# ATSAMC21N register map
Vendor: Microchip Technology Inc.; Series: SAMC21; File version: A
CPU: CM0+ r0p1, little endian, MPU, no FPU, VTOR, 2 interrupt priority bits, 31 interrupts
Registers are 32-bit, read-write, reset 0x0 unless marked. A register's access mark holds for its fields unless they carry their own. Offsets are from the block's base; [hi:lo] are bit positions; {n}, {i} and the like mark numbered series; 'fields as' and 'values as' point back to an identical list.

## AC — Analog Comparators
Base 0x42005000; register names take the prefix AC_
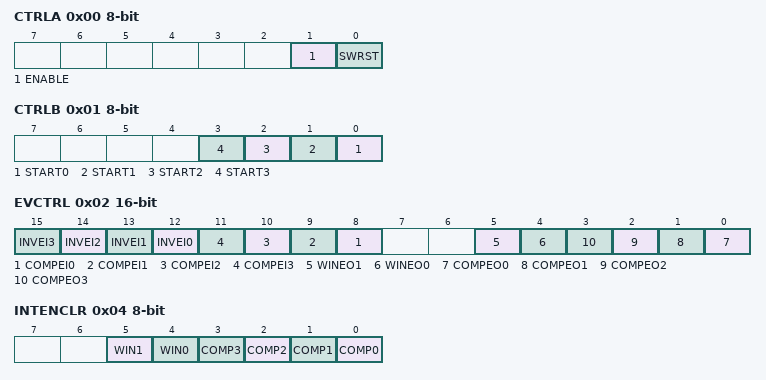
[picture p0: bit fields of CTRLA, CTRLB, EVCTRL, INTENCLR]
0x00 CTRLA 8-bit — Control A
  [1] ENABLE
  [0] SWRST wo — Software Reset
0x01 CTRLB 8-bit wo — Control B
  [n] START{n} (n=0..3) — Comparator {n} Start Comparison
0x02 EVCTRL 16-bit — Event Control
  [n+12] INVEI{n} (n=0..3) — Comparator {n} Input Event Invert Enable
  [n+8] COMPEI{n} (n=0..3) — Comparator {n} Event Input Enable
  [5] WINEO1 — Window 1 Event Output Enable
  [4] WINEO0 — Window 0 Event Output Enable
  [n] COMPEO{n} (n=0..3) — Comparator {n} Event Output Enable
0x04 INTENCLR 8-bit — Interrupt Enable Clear
  [5] WIN1 — Window 1 Interrupt Enable
  [4] WIN0 — Window 0 Interrupt Enable
  [n] COMP{n} (n=0..3) — Comparator {n} Interrupt Enable
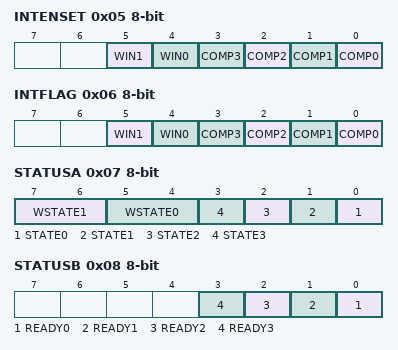
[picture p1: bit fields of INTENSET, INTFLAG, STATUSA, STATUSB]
0x05 INTENSET 8-bit — Interrupt Enable Set
  fields as INTENCLR
0x06 INTFLAG 8-bit — Interrupt Flag Status and Clear
  [5] WIN1 — Window 1
  [4] WIN0 — Window 0
  [n] COMP{n} (n=0..3) — Comparator {n}
0x07 STATUSA 8-bit ro
  [7:6] WSTATE1 — Window 1 Current State
    0=ABOVE (Signal is above window); 1=INSIDE (Signal is inside window); 2=BELOW (Signal is below window)
  [5:4] WSTATE0 — Window 0 Current State
    values as WSTATE1
  [n] STATE{n} (n=0..3) — Comparator {n} Current State
0x08 STATUSB 8-bit ro
  [n] READY{n} (n=0..3) — Comparator {n} Ready
0x09 DBGCTRL 8-bit — Debug Control
  [0] DBGRUN — Debug Run
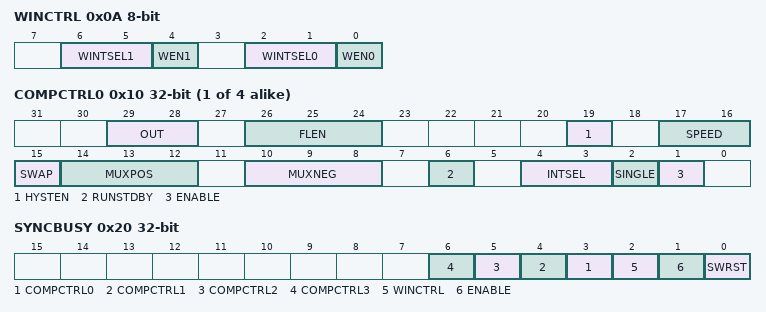
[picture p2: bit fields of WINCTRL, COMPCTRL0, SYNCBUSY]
0x0A WINCTRL 8-bit — Window Control
  [6:5] WINTSEL1 — Window 1 Interrupt Selection
    0=ABOVE (Interrupt on signal above window); 1=INSIDE (Interrupt on signal inside window); 2=BELOW (Interrupt on signal below window); 3=OUTSIDE (Interrupt on signal outside window)
  [4] WEN1 — Window 1 Mode Enable
  [2:1] WINTSEL0 — Window 0 Interrupt Selection
    values as WINTSEL1
  [0] WEN0 — Window 0 Mode Enable
{0xC+i} SCALER{i} (i=0..3) 8-bit — Scaler n
  [5:0] VALUE — Scaler Value
{0x10+4i} COMPCTRL{i} (i=0..3) — Comparator Control n
  [29:28] OUT — Output
    0=OFF (The output of COMPn is not routed to the COMPn I/O port); 1=ASYNC (The asynchronous output of COMPn is routed to the COMPn I/O port); 2=SYNC (The synchronous output (including filtering) of COMPn is routed to the COMPn I/O port)
  [26:24] FLEN — Filter Length
    0=OFF (No filtering); 1=MAJ3 (3-bit majority function (2 of 3)); 2=MAJ5 (5-bit majority function (3 of 5))
  [19] HYSTEN — Hysteresis Enable
  [17:16] SPEED — Speed Selection
    0=LOW (Low speed); 3=HIGH (High speed)
  [15] SWAP — Swap Inputs and Invert
  [14:12] MUXPOS — Positive Input Mux Selection
    {v}=PIN{v} (I/O pin {v}) (v=0..3); 4=VSCALE (VDD Scaler)
  [10:8] MUXNEG — Negative Input Mux Selection
    {v}=PIN{v} (I/O pin {v}) (v=0..3); 4=GND (Ground); 5=VSCALE (VDD scaler); 6=BANDGAP (Internal bandgap voltage); 7=DAC (DAC output)
  [6] RUNSTDBY — Run in Standby
  [4:3] INTSEL — Interrupt Selection
    0=TOGGLE (Interrupt on comparator output toggle); 1=RISING (Interrupt on comparator output rising); 2=FALLING (Interrupt on comparator output falling); 3=EOC (Interrupt on end of comparison (single-shot mode only))
  [2] SINGLE — Single-Shot Mode
  [1] ENABLE
0x20 SYNCBUSY ro — Synchronization Busy
  [n+3] COMPCTRL{n} (n=0..3) — COMPCTRL {n} Synchronization Busy
  [2] WINCTRL — WINCTRL Synchronization Busy
  [1] ENABLE — Enable Synchronization Busy
  [0] SWRST — Software Reset Synchronization Busy

## CCL — Configurable Custom Logic
Base 0x42005C00; register names take the prefix CCL_
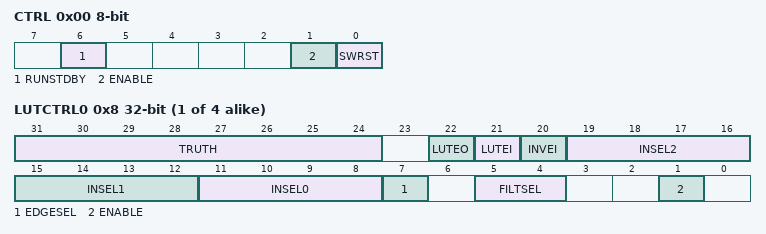
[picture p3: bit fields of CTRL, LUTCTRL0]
0x00 CTRL 8-bit — Control
  [6] RUNSTDBY — Run during Standby
  [1] ENABLE
  [0] SWRST wo — Software Reset
{0x4+i} SEQCTRL{i} (i=0..1) 8-bit — SEQ Control x
  [3:0] SEQSEL — Sequential Selection
    0=DISABLE (Sequential logic is disabled); 1=DFF (D flip flop); 2=JK (JK flip flop); 3=LATCH (D latch); 4=RS (RS latch)
{0x8+4i} LUTCTRL{i} (i=0..3) — LUT Control x
  [31:24] TRUTH — Truth Value
  [22] LUTEO — Event Output Enable
  [21] LUTEI — Event Input Enable
  [20] INVEI — Input Event Invert
  [19:16] INSEL2 — Input Selection 2
  [15:12] INSEL1 — Input Selection 1
  [11:8] INSEL0 — Input Selection 0
    0=MASK (Masked input); 1=FEEDBACK (Feedback input source); 2=LINK (Linked LUT input source); 3=EVENT (Event in put source); 4=IO (I/O pin input source); 5=AC (AC input source); 6=TC (TC input source); 7=ALTTC (Alternate TC input source); 8=TCC (TCC input source); 9=SERCOM (SERCOM inout source); 10=ALT2TC (Alternate 2 TC input source); 11=ASYNCEVENT (ASYNC EVENT input source. The EVENT input will bypass edge detection logic.)
  [7] EDGESEL — Edge Selection
  [5:4] FILTSEL — Filter Selection
    0=DISABLE (Filter disabled); 1=SYNCH (Synchronizer enabled); 2=FILTER (Filter enabled)
  [1] ENABLE — LUT Enable
